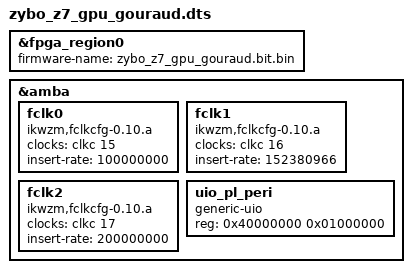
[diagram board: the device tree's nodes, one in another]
/dts-v1/; /plugin/;

/ {
    fragment@0 {
//      target = <&fpga_full>;
        target = <&fpga_region0>;
        __overlay__ {
            #address-cells = <1>;
            #size-cells = <1>;

            firmware-name = "zybo_z7_gpu_gouraud.bit.bin";
        };
    };

    fragment@1 {
//      target-path = "/amba";
        target = <&amba>;
        __overlay__ {
            fclk0 {
                compatible  = "ikwzm,fclkcfg-0.10.a";
                clocks      = <&clkc 15>;
                insert-rate = "100000000";
            };
            fclk1 {
                compatible  = "ikwzm,fclkcfg-0.10.a";
                clocks      = <&clkc 16>;
                insert-rate = "152380966";
            };
            fclk2 {
                compatible  = "ikwzm,fclkcfg-0.10.a";
                clocks      = <&clkc 17>;
                insert-rate = "200000000";
            };
        };
    };

    fragment@2 {
//      target-path = "/amba";
        target = <&amba>;
        __overlay__ {
            #address-cells = <0x1>;
            #size-cells = <0x1>;
            
            uio_pl_peri {
                compatible = "generic-uio";
                reg = <0x40000000 0x01000000>;
            };

            /*
            udmabuf4 {
                compatible = "ikwzm,udmabuf-0.10.a";
                minor-number = <4>;
                size = <0x00400000>;
            };
            */
        };
    };
};


